AUTOSAR XML (schema 00050)
package /FCADT/ComponentTypes
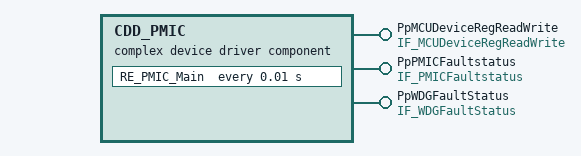
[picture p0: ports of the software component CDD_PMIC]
  complex device driver sw component type CDD_PMIC
    provide port PpMCUDeviceRegReadWrite: provided-interface=IF_MCUDeviceRegReadWrite
      provided-com-specs:
        operation=MCUReadDeviceReg, queue-length=1
        operation=MCUReadDeviceRegData, queue-length=1
        operation=MCUWriteDeviceReg, queue-length=1
    provide port PpPMICFaultstatus: nonqueued-sender-com-spec{data-element=Sts, init-value=8 x 0}, provided-interface=IF_PMICFaultstatus
    provide port PpWDGFaultStatus: nonqueued-sender-com-spec{data-element=Sts, init-value=[0, 0]}, provided-interface=IF_WDGFaultStatus
    behavior CDD_PMIC_InternalBehavior: handle-termination-and-restart=NO-SUPPORT, port-api-option{enable-take-address=false, indirect-api=false, port=PpMCUDeviceRegReadWrite}
      init event InitEvent: start-on-event=RE_PMIC_Init
      timing event TMT_RE_PMIC_Main: start-on-event=RE_PMIC_Main, period=0.01
      operation invoked event OIT_RE_MCUReadDeviceReg_PpMCUDeviceRegReadWrite_MCUReadDeviceReg: start-on-event=RE_MCUReadDeviceReg, operation=PpMCUDeviceRegReadWrite.MCUReadDeviceReg
      operation invoked event OIT_RE_MCUReadDeviceRegData_PpMCUDeviceRegReadWrite_MCUReadDeviceRegData: start-on-event=RE_MCUReadDeviceRegData, operation=PpMCUDeviceRegReadWrite.MCUReadDeviceRegData
      operation invoked event OIT_RE_MCUWriteDeviceReg_PpMCUDeviceRegReadWrite_MCUWriteDeviceReg: start-on-event=RE_MCUWriteDeviceReg, operation=PpMCUDeviceRegReadWrite.MCUWriteDeviceReg
      5 x runnable:
        RE_PMIC_Init
        RE_PMIC_Main
          data-send-points:
            access SEND_PpPMICFaultstatus_Sts: accessed-variable=PpPMICFaultstatus.Sts
            access SEND_PpWDGFaultStatus_Sts: accessed-variable=PpWDGFaultStatus.Sts
        RE_MCUReadDeviceReg: can-be-invoked-concurrently=true
        RE_MCUReadDeviceRegData: can-be-invoked-concurrently=true
        RE_MCUWriteDeviceReg: can-be-invoked-concurrently=true
  swc implementation CDD_PMIC_Implementation: programming-language=C, vendor-id=0, behavior=CDD_PMIC_InternalBehavior
    code-descriptors:
      code Default: artifact-descriptors=autosar-engineering-object=category=SWSRC
